VERSION ""

NS_ :

BS_:

BU_: VCU

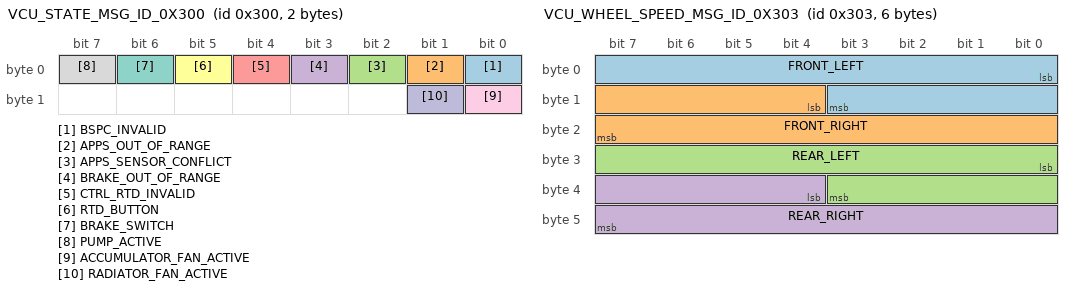
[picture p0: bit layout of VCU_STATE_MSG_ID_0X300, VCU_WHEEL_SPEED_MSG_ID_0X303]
BO_ 768 VCU_STATE_MSG_ID_0X300: 2 VCU
 SG_ BSPC_INVALID : 0|1@1+ (1,0) [0|1] "bool" Vector__XXX
 SG_ APPS_OUT_OF_RANGE : 1|1@1+ (1,0) [0|1] "bool" Vector__XXX
 SG_ APPS_SENSOR_CONFLICT : 2|1@1+ (1,0) [0|1] "bool" Vector__XXX
 SG_ BRAKE_OUT_OF_RANGE : 3|1@1+ (1,0) [0|1] "bool" Vector__XXX
 SG_ CTRL_RTD_INVALID : 4|1@1+ (1,0) [0|1] "bool" Vector__XXX
 SG_ RTD_BUTTON : 5|1@1+ (1,0) [0|1] "bool" Vector__XXX
 SG_ BRAKE_SWITCH : 6|1@1+ (1,0) [0|1] "bool" Vector__XXX
 SG_ PUMP_ACTIVE : 7|1@1+ (1,0) [0|1] "bool" Vector__XXX
 SG_ ACCUMULATOR_FAN_ACTIVE : 8|1@1+ (1,0) [0|1] "bool" Vector__XXX
 SG_ RADIATOR_FAN_ACTIVE : 9|1@1+ (1,0) [0|1] "bool" Vector__XXX

BO_ 769 VCU_SENSORS_MSG_ID_0X301: 4 VCU
 SG_ ACCELERATOR_POSITION : 0|16@1+ (0.1,0) [0|100] "%" Vector__XXX
 SG_ BRAKE_PRESSURE : 16|16@1- (0.1,0) [0|2000] "PSI" Vector__XXX

BO_ 770 VCU_COOLANT_MSG_ID_0X302: 2 VCU
 SG_ MOTOR_FLOW_RATE: 0|8@1+ (0.1,0) [0|30] "L/min" Vector__XXX
 SG_ INVERTER_FLOW_RATE : 8|8@1+ (0.1,0) [0|30] "L/min" Vector__XXX

BO_ 771 VCU_WHEEL_SPEED_MSG_ID_0X303: 6 VCU
 SG_ FRONT_LEFT : 0|12@1+ (1,0) [0|0] "rpm" Vector__XXX
 SG_ FRONT_RIGHT : 12|12@1+ (1,0) [0|0] "rpm" Vector__XXX
 SG_ REAR_LEFT : 24|12@1+ (1,0) [0|0] "rpm" Vector__XXX
 SG_ REAR_RIGHT : 36|12@1+ (1,0) [0|0] "rpm" Vector__XXX

BO_ 772 VCU_IMD_MSG_ID_0X304: 3 VCU
 SG_ STATE : 0|8@1+ (1,0) [0|5] "" Vector__XXX
 SG_ RESISTANCE : 8|16@1+ (1,0) [0|10000] "kOhm" Vector__XXX

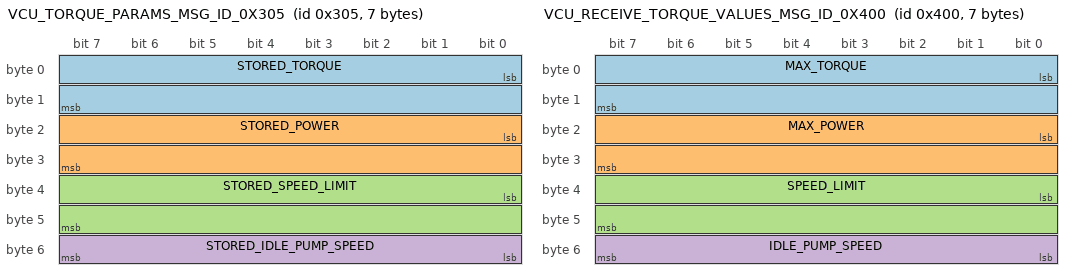
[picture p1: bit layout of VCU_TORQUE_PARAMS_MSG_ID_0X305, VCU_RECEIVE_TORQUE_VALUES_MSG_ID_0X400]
BO_ 773 VCU_TORQUE_PARAMS_MSG_ID_0X305: 7 VCU
 SG_ STORED_TORQUE : 0|16@1- (0.1, 0) [-3276.8|3276.7] "Nm" Vector__XXX
 SG_ STORED_POWER : 16|16@1+ (0.1,0) [0|6553.5] "kW" Vector__XXX
 SG_ STORED_SPEED_LIMIT : 32|16@1+ (1,0) [0|65535] "rpm" Vector__XXX
 SG_ STORED_IDLE_PUMP_SPEED: 48|8@1+ (1,0) [0|100] "%" Vector__XXX

BO_ 774 VCU_FLOW_SENSOR_RATE_MSG_ID_0X306: 2 VCU
 SG_ FLOW_RATE: 0|16@1+ (0.1,0) [0|65535] "L/min" Vector__XXX

BO_ 775 VCU_AMS_DTC_PARAMS_MSG_ID_0X307: 4 VCU
 SG_ STORED_DTC1_MASK : 0|16@1+ (1,0) [0|0] "" Vector__XXX
 SG_ STORED_DTC2_MASK : 16|16@1+ (1,0) [0|0] "" Vector__XXX

BO_ 1024 VCU_RECEIVE_TORQUE_VALUES_MSG_ID_0X400: 7 Vector__XXX
 SG_ MAX_TORQUE : 0|16@1- (0.1,0) [-3276.8|3276.7] "Nm" VCU
 SG_ MAX_POWER : 16|16@1+ (0.1,0) [0|6553.5] "kW" VCU
 SG_ SPEED_LIMIT : 32|16@1+ (1,0) [0|65535] "rpm" VCU
 SG_ IDLE_PUMP_SPEED : 48|8@1+ (1,0) [0|100] "%" VCU

BO_ 1025 VCU_RECEIVE_AMS_DTC_MASK_MSG_ID_0X401: 4 Vector__XXX
 SG_ DTC1_MASK : 0|16@1+ (1,0) [0|0] "" VCU
 SG_ DTC2_MASK : 16|16@1+ (1,0) [0|0] "" VCU

BA_DEF_  "BusType" STRING ;
BA_DEF_DEF_  "BusType" "CAN";
